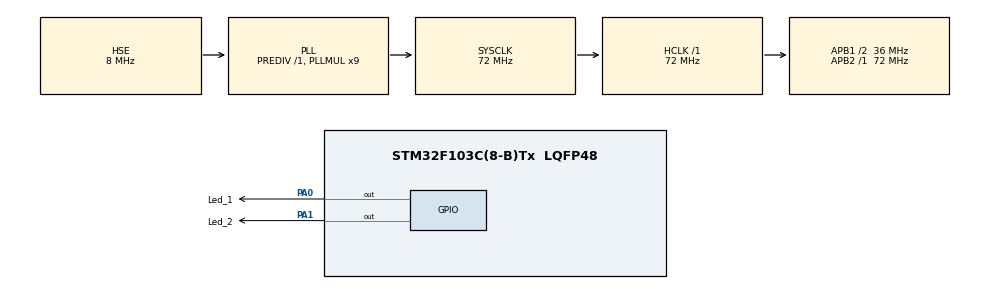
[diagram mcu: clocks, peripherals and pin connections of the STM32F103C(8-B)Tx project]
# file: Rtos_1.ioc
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FREERTOS.INCLUDE_vTaskDelayUntil=1
FREERTOS.Tasks01=defaultTask,0,128,StartDefaultTask,Default,NULL,Dynamic,NULL,NULL;Task2,0,128,Task2_init,Default,NULL,Dynamic,NULL,NULL
Mcu.Family=STM32F1
Mcu.Name=STM32F103C(8-B)Tx
Mcu.Package=LQFP48
NVIC.PriorityGroup=NVIC_PRIORITYGROUP_4
NVIC.TIM1_UP_IRQn=true\:15\:0\:false\:false\:true\:false\:false\:true\:true
NVIC.TimeBase=TIM1_UP_IRQn
NVIC.TimeBaseIP=TIM1
PA0-WKUP.GPIO_Label=Led_1
PA0-WKUP.Signal=GPIO_Output
PA1.GPIO_Label=Led_2
PA1.Signal=GPIO_Output
PA13.Mode=Serial_Wire
PA13.Signal=SYS_JTMS-SWDIO
PA14.Mode=Serial_Wire
PA14.Signal=SYS_JTCK-SWCLK
PD0-OSC_IN.Mode=HSE-External-Oscillator
PD0-OSC_IN.Signal=RCC_OSC_IN
PD1-OSC_OUT.Mode=HSE-External-Oscillator
PD1-OSC_OUT.Signal=RCC_OSC_OUT
ProjectManager.HeapSize=0x200
ProjectManager.StackSize=0x400
ProjectManager.TargetToolchain=STM32CubeIDE
RCC.AHBFreq_Value=72000000
RCC.APB1CLKDivider=RCC_HCLK_DIV2
RCC.APB1Freq_Value=36000000
RCC.APB1TimFreq_Value=72000000
RCC.APB2Freq_Value=72000000
RCC.APB2TimFreq_Value=72000000
RCC.HCLKFreq_Value=72000000
RCC.PLLMUL=RCC_PLL_MUL9
RCC.PLLSourceVirtual=RCC_PLLSOURCE_HSE
RCC.SYSCLKFreq_VALUE=72000000
RCC.SYSCLKSource=RCC_SYSCLKSOURCE_PLLCLK
RCC.USBFreq_Value=72000000
VP_FREERTOS_VS_CMSIS_V1.Mode=CMSIS_V1
VP_SYS_VS_tim1.Mode=TIM1
board=custom

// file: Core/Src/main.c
/* USER CODE BEGIN Header */
/**
  ******************************************************************************
  * @file           : main.c
  * @brief          : Main program body
  ******************************************************************************
  * @attention
  *
  * Copyright (c) 2025 STMicroelectronics.
  * All rights reserved.
  *
  * This software is licensed under terms that can be found in the LICENSE file
  * in the root directory of this software component.
  * If no LICENSE file comes with this software, it is provided AS-IS.
  *
  ******************************************************************************
  */
/* USER CODE END Header */
#include "main.h"
#include "cmsis_os.h"

osThreadId defaultTaskHandle;
osThreadId Task2Handle;

void SystemClock_Config(void);
static void MX_GPIO_Init(void);
void StartDefaultTask(void const * argument);
void Task2_init(void const * argument);

/* USER CODE BEGIN 0 */
uint8_t counter = 0;
/* USER CODE END 0 */

int main(void)
{

  /* MCU Configuration--------------------------------------------------------*/

  /* Reset of all peripherals, Initializes the Flash interface and the Systick. */
  HAL_Init();

  /* Configure the system clock */
  SystemClock_Config();

  /* Initialize all configured peripherals */
  MX_GPIO_Init();
  /* USER CODE BEGIN 2 */
  HAL_GPIO_WritePin(Led_1_GPIO_Port, Led_1_Pin, GPIO_PIN_SET);
  HAL_GPIO_WritePin(Led_2_GPIO_Port, Led_2_Pin, GPIO_PIN_SET);
  HAL_Delay(2000);
  HAL_GPIO_WritePin(Led_1_GPIO_Port, Led_1_Pin, GPIO_PIN_RESET);
  HAL_GPIO_WritePin(Led_2_GPIO_Port, Led_2_Pin, GPIO_PIN_RESET);
  /* USER CODE END 2 */

  /* Create the thread(s) */
  /* definition and creation of defaultTask */
  osThreadDef(defaultTask, StartDefaultTask, osPriorityBelowNormal, 0, 128);
  defaultTaskHandle = osThreadCreate(osThread(defaultTask), NULL);

  /* definition and creation of Task2 */
  osThreadDef(Task2, Task2_init, osPriorityAboveNormal, 0, 128);
  Task2Handle = osThreadCreate(osThread(Task2), NULL);

  /* Start scheduler */
  osKernelStart();

  /* We should never get here as control is now taken by the scheduler */

  /* Infinite loop */
  while (1)
  {

  }
}

void SystemClock_Config(void)
{
  RCC_OscInitTypeDef RCC_OscInitStruct = {0};
  RCC_ClkInitTypeDef RCC_ClkInitStruct = {0};

  /** Initializes the RCC Oscillators according to the specified parameters
  * in the RCC_OscInitTypeDef structure.
  */
  RCC_OscInitStruct.OscillatorType = RCC_OSCILLATORTYPE_HSE;
  RCC_OscInitStruct.HSEState = RCC_HSE_ON;
  RCC_OscInitStruct.HSEPredivValue = RCC_HSE_PREDIV_DIV1;
  RCC_OscInitStruct.HSIState = RCC_HSI_ON;
  RCC_OscInitStruct.PLL.PLLState = RCC_PLL_ON;
  RCC_OscInitStruct.PLL.PLLSource = RCC_PLLSOURCE_HSE;
  RCC_OscInitStruct.PLL.PLLMUL = RCC_PLL_MUL9;
  if (HAL_RCC_OscConfig(&RCC_OscInitStruct) != HAL_OK)
  {
    Error_Handler();
  }

  /** Initializes the CPU, AHB and APB buses clocks
  */
  RCC_ClkInitStruct.ClockType = RCC_CLOCKTYPE_HCLK|RCC_CLOCKTYPE_SYSCLK
                              |RCC_CLOCKTYPE_PCLK1|RCC_CLOCKTYPE_PCLK2;
  RCC_ClkInitStruct.SYSCLKSource = RCC_SYSCLKSOURCE_PLLCLK;
  RCC_ClkInitStruct.AHBCLKDivider = RCC_SYSCLK_DIV1;
  RCC_ClkInitStruct.APB1CLKDivider = RCC_HCLK_DIV2;
  RCC_ClkInitStruct.APB2CLKDivider = RCC_HCLK_DIV1;

  if (HAL_RCC_ClockConfig(&RCC_ClkInitStruct, FLASH_LATENCY_2) != HAL_OK)
  {
    Error_Handler();
  }
}

static void MX_GPIO_Init(void)
{
  GPIO_InitTypeDef GPIO_InitStruct = {0};

  /* GPIO Ports Clock Enable */
  __HAL_RCC_GPIOD_CLK_ENABLE();
  __HAL_RCC_GPIOA_CLK_ENABLE();

  /*Configure GPIO pin Output Level */
  HAL_GPIO_WritePin(GPIOA, Led_1_Pin|Led_2_Pin, GPIO_PIN_RESET);

  /*Configure GPIO pins : Led_1_Pin Led_2_Pin */
  GPIO_InitStruct.Pin = Led_1_Pin|Led_2_Pin;
  GPIO_InitStruct.Mode = GPIO_MODE_OUTPUT_PP;
  GPIO_InitStruct.Pull = GPIO_NOPULL;
  GPIO_InitStruct.Speed = GPIO_SPEED_FREQ_LOW;
  HAL_GPIO_Init(GPIOA, &GPIO_InitStruct);

}

void StartDefaultTask(void const * argument)
{
  /* USER CODE BEGIN 5 */
  /* Infinite loop */
  for(;;)
  {
	  counter++;
	  HAL_GPIO_WritePin(Led_1_GPIO_Port, Led_1_Pin, GPIO_PIN_SET);
	  osDelay(500);
	  HAL_GPIO_WritePin(Led_1_GPIO_Port, Led_1_Pin, GPIO_PIN_RESET);
	  osDelay(500);
  }
  /* USER CODE END 5 */
}

void Task2_init(void const * argument)
{
  /* USER CODE BEGIN Task2_init */
  /* Infinite loop */
  for(;;)
  {
	  if(counter < 10){
		  HAL_GPIO_WritePin(Led_2_GPIO_Port, Led_2_Pin, GPIO_PIN_SET);
		  osDelay(500);
		  HAL_GPIO_WritePin(Led_2_GPIO_Port, Led_2_Pin, GPIO_PIN_RESET);
		  osDelay(500);
	  }
	  else if (counter >= 10 && counter < 20){
		  osThreadSuspend(defaultTaskHandle);
		  HAL_GPIO_WritePin(Led_2_GPIO_Port, Led_2_Pin, GPIO_PIN_SET);
		  osDelay(500);
		  HAL_GPIO_WritePin(Led_2_GPIO_Port, Led_2_Pin, GPIO_PIN_RESET);
		  osDelay(500);
		  counter++;
	  }
	  else{
		  osThreadResume(defaultTaskHandle);
		  HAL_GPIO_WritePin(Led_2_GPIO_Port, Led_2_Pin, GPIO_PIN_SET);
		  osDelay(500);
		  HAL_GPIO_WritePin(Led_2_GPIO_Port, Led_2_Pin, GPIO_PIN_RESET);
		  osDelay(500);
		  counter = 0;
	  }
  }
  /* USER CODE END Task2_init */
}

void HAL_TIM_PeriodElapsedCallback(TIM_HandleTypeDef *htim)
{
  if (htim->Instance == TIM1)
  {
    HAL_IncTick();
  }
}

void Error_Handler(void)
{
  __disable_irq();
  while (1)
  {
  }
}
